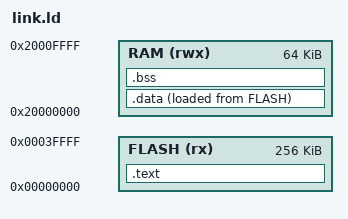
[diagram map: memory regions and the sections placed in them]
/* 有 .data 的完整链接脚本：注意 _sidata = LOADADDR(.data)，
 * 否则 .data 的初值不知道从 FLASH 哪里读。 */
MEMORY {
  FLASH (rx)  : ORIGIN = 0x00000000, LENGTH = 256K
  RAM   (rwx) : ORIGIN = 0x20000000, LENGTH = 64K
}
ENTRY(reset_handler)
SECTIONS {
  .text : {
    KEEP(*(.vectors))
    *(.text*)
    *(.rodata*)
  } > FLASH

  .data : {
    _sdata = .;
    *(.data*)
    _edata = .;
  } > RAM AT > FLASH
  _sidata = LOADADDR(.data);

  .bss : {
    _sbss = .;
    *(.bss*) *(COMMON)
    _ebss = .;
  } > RAM
}
